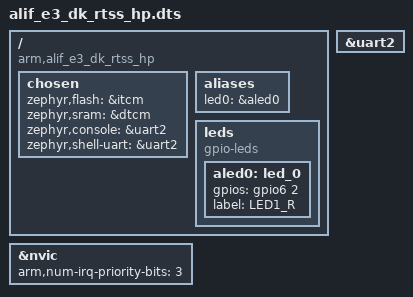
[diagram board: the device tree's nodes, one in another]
/* Copyright (c) 2024 Alif Semiconductor
 *
 * SPDX-License-Identifier: Apache-2.0
 */
/dts-v1/;

#include <alif/e3_rtss_common.dtsi>
#include <alif/ensemble_rtss_hp.dtsi>
#include <alif/ensemble-pinctrl.dtsi>

/ {
	compatible = "arm,alif_e3_dk_rtss_hp";
	#address-cells = <1>;
	#size-cells = <1>;

	chosen {
		zephyr,flash = &itcm;
		zephyr,sram = &dtcm;
		zephyr,console = &uart2;
		zephyr,shell-uart = &uart2;
	};

	aliases {
		led0 = &aled0;
	};
	leds {
		compatible = "gpio-leds";
		aled0: led_0 {
			gpios = <&gpio6 2 0>;
			label = "LED1_R";
		};
	};
};
&uart2 {
	status = "okay";
};
&nvic {
	arm,num-irq-priority-bits = <3>;
};
